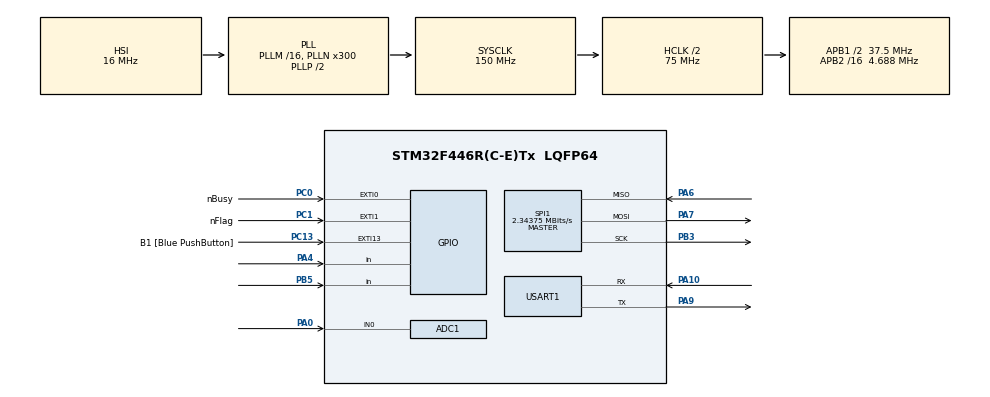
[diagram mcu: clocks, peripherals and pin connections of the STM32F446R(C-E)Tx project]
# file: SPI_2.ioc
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ADC1.Channel-1\#ChannelRegularConversion=ADC_CHANNEL_0
ADC1.NbrOfConversionFlag=1
ADC1.Rank-1\#ChannelRegularConversion=1
ADC1.SamplingTime-1\#ChannelRegularConversion=ADC_SAMPLETIME_3CYCLES
ADC1.master=1
FREERTOS.Tasks01=defaultTask,24,128,StartDefaultTask,Default,NULL,Dynamic,NULL,NULL
FREERTOS.configUSE_NEWLIB_REENTRANT=1
Mcu.Family=STM32F4
Mcu.Name=STM32F446R(C-E)Tx
Mcu.Package=LQFP64
NVIC.EXTI0_IRQn=true\:5\:0\:false\:false\:true\:true\:true\:true\:true
NVIC.EXTI15_10_IRQn=true\:5\:0\:false\:false\:true\:true\:true\:true\:true
NVIC.EXTI1_IRQn=true\:5\:0\:false\:false\:true\:true\:true\:true\:true
NVIC.PriorityGroup=NVIC_PRIORITYGROUP_4
NVIC.TIM1_UP_TIM10_IRQn=true\:15\:0\:false\:false\:true\:false\:false\:true\:true
NVIC.TimeBase=TIM1_UP_TIM10_IRQn
NVIC.TimeBaseIP=TIM1
PA0-WKUP.Signal=ADCx_IN0
PA10.Mode=Asynchronous
PA10.Signal=USART1_RX
PA13.GPIO_Label=TMS
PA13.Mode=Serial_Wire
PA13.Signal=SYS_JTMS-SWDIO
PA14.GPIO_Label=TCK
PA14.Mode=Serial_Wire
PA14.Signal=SYS_JTCK-SWCLK
PA2.GPIO_Label=USART_TX
PA2.Signal=USART2_TX
PA3.GPIO_Label=USART_RX
PA3.Signal=USART2_RX
PA4.Signal=GPIO_Input
PA6.Mode=Full_Duplex_Master
PA6.Signal=SPI1_MISO
PA7.Mode=Full_Duplex_Master
PA7.Signal=SPI1_MOSI
PA9.Mode=Asynchronous
PA9.Signal=USART1_TX
PB3.Mode=Full_Duplex_Master
PB3.Signal=SPI1_SCK
PB5.Signal=GPIO_Input
PC0.GPIO_Label=nBusy
PC0.Signal=GPXTI0
PC1.GPIO_Label=nFlag
PC1.Signal=GPXTI1
PC13.GPIO_Label=B1 [Blue PushButton]
PC13.GPIO_ModeDefaultEXTI=GPIO_MODE_IT_FALLING
PC13.Signal=GPXTI13
PC14-OSC32_IN.Mode=LSE-External-Oscillator
PC14-OSC32_IN.Signal=RCC_OSC32_IN
PC15-OSC32_OUT.Mode=LSE-External-Oscillator
PC15-OSC32_OUT.Signal=RCC_OSC32_OUT
PH0-OSC_IN.Mode=HSE-External-Oscillator
PH0-OSC_IN.Signal=RCC_OSC_IN
PH1-OSC_OUT.Mode=HSE-External-Oscillator
PH1-OSC_OUT.Signal=RCC_OSC_OUT
ProjectManager.HeapSize=0x200
ProjectManager.StackSize=0x400
ProjectManager.TargetToolchain=STM32CubeIDE
RCC.48MHZClocksFreq_Value=84000000
RCC.AHBCLKDivider=RCC_SYSCLK_DIV2
RCC.AHBFreq_Value=75000000
RCC.APB1CLKDivider=RCC_HCLK_DIV2
RCC.APB1Freq_Value=37500000
RCC.APB1TimFreq_Value=75000000
RCC.APB2CLKDivider=RCC_HCLK_DIV16
RCC.APB2Freq_Value=4687500
RCC.APB2TimFreq_Value=9375000
RCC.CortexFreq_Value=75000000
RCC.FLatency-AdvancedSettings=FLASH_LATENCY_2
RCC.HCLKFreq_Value=75000000
RCC.HSE_VALUE=8000000
RCC.HSI_VALUE=16000000
RCC.PLLN=300
RCC.SYSCLKFreq_VALUE=150000000
RCC.SYSCLKSource=RCC_SYSCLKSOURCE_PLLCLK
RCC.USBFreq_Value=150000000
RCC.VCOOutputFreq_Value=300000000
SH.ADCx_IN0.0=ADC1_IN0,IN0
SPI1.CalculateBaudRate=2.34375 MBits/s
SPI1.Direction=SPI_DIRECTION_2LINES
SPI1.Mode=SPI_MODE_MASTER
SPI1.VirtualType=VM_MASTER
USART1.VirtualMode=VM_ASYNC
VP_FREERTOS_VS_CMSIS_V2.Mode=CMSIS_V2
VP_SYS_VS_tim1.Mode=TIM1
board=NUCLEO-F446RE

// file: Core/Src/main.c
/* USER CODE BEGIN Header */
/**
 ******************************************************************************
 * @file           : main.c
 * @brief          : Main program body
 ******************************************************************************
 * @attention
 *
 * Copyright (c) 2024 STMicroelectronics.
 * All rights reserved.
 *
 * This software is licensed under terms that can be found in the LICENSE file
 * in the root directory of this software component.
 * If no LICENSE file comes with this software, it is provided AS-IS.
 *
 ******************************************************************************
 */
/* USER CODE END Header */
#include "main.h"
#include "cmsis_os.h"

/* USER CODE BEGIN Includes */

#include "xnucleoihm02a1.h"
#include "example.h"

/* USER CODE END Includes */

ADC_HandleTypeDef hadc1;

SPI_HandleTypeDef hspi1;

UART_HandleTypeDef huart1;

/* Definitions for defaultTask */
osThreadId_t defaultTaskHandle;
const osThreadAttr_t defaultTask_attributes = {
  .name = "defaultTask",
  .stack_size = 128 * 4,
  .priority = (osPriority_t) osPriorityNormal,
};

void SystemClock_Config(void);
static void MX_GPIO_Init(void);
static void MX_ADC1_Init(void);
static void MX_SPI1_Init(void);
static void MX_USART1_UART_Init(void);
void StartDefaultTask(void *argument);

int main(void)
{

  /* MCU Configuration--------------------------------------------------------*/

  /* Reset of all peripherals, Initializes the Flash interface and the Systick. */
  HAL_Init();

  /* Configure the system clock */
  SystemClock_Config();

  /* Initialize all configured peripherals */
  MX_GPIO_Init();
  MX_ADC1_Init();
  MX_SPI1_Init();
  MX_USART1_UART_Init();
  /* USER CODE BEGIN 2 */

	/* Init specifique du XNUCLEO02A01 */
	BSP_Init();

  /* USER CODE END 2 */

  /* Init scheduler */
  osKernelInitialize();

  /* Create the thread(s) */
  /* creation of defaultTask */
  defaultTaskHandle = osThreadNew(StartDefaultTask, NULL, &defaultTask_attributes);

  /* Start scheduler */
  osKernelStart();

  /* We should never get here as control is now taken by the scheduler */

  /* Infinite loop */
	while (1)
	{

	}
}

void SystemClock_Config(void)
{
  RCC_OscInitTypeDef RCC_OscInitStruct = {0};
  RCC_ClkInitTypeDef RCC_ClkInitStruct = {0};

  /** Configure the main internal regulator output voltage
  */
  __HAL_RCC_PWR_CLK_ENABLE();
  __HAL_PWR_VOLTAGESCALING_CONFIG(PWR_REGULATOR_VOLTAGE_SCALE3);

  /** Initializes the RCC Oscillators according to the specified parameters
  * in the RCC_OscInitTypeDef structure.
  */
  RCC_OscInitStruct.OscillatorType = RCC_OSCILLATORTYPE_HSI;
  RCC_OscInitStruct.HSIState = RCC_HSI_ON;
  RCC_OscInitStruct.HSICalibrationValue = RCC_HSICALIBRATION_DEFAULT;
  RCC_OscInitStruct.PLL.PLLState = RCC_PLL_ON;
  RCC_OscInitStruct.PLL.PLLSource = RCC_PLLSOURCE_HSI;
  RCC_OscInitStruct.PLL.PLLM = 16;
  RCC_OscInitStruct.PLL.PLLN = 300;
  RCC_OscInitStruct.PLL.PLLP = RCC_PLLP_DIV2;
  RCC_OscInitStruct.PLL.PLLQ = 2;
  RCC_OscInitStruct.PLL.PLLR = 2;
  if (HAL_RCC_OscConfig(&RCC_OscInitStruct) != HAL_OK)
  {
    Error_Handler();
  }

  /** Initializes the CPU, AHB and APB buses clocks
  */
  RCC_ClkInitStruct.ClockType = RCC_CLOCKTYPE_HCLK|RCC_CLOCKTYPE_SYSCLK
                              |RCC_CLOCKTYPE_PCLK1|RCC_CLOCKTYPE_PCLK2;
  RCC_ClkInitStruct.SYSCLKSource = RCC_SYSCLKSOURCE_PLLCLK;
  RCC_ClkInitStruct.AHBCLKDivider = RCC_SYSCLK_DIV2;
  RCC_ClkInitStruct.APB1CLKDivider = RCC_HCLK_DIV2;
  RCC_ClkInitStruct.APB2CLKDivider = RCC_HCLK_DIV16;

  if (HAL_RCC_ClockConfig(&RCC_ClkInitStruct, FLASH_LATENCY_2) != HAL_OK)
  {
    Error_Handler();
  }
}

static void MX_ADC1_Init(void)
{

  ADC_ChannelConfTypeDef sConfig = {0};

  /** Configure the global features of the ADC (Clock, Resolution, Data Alignment and number of conversion)
  */
  hadc1.Instance = ADC1;
  hadc1.Init.ClockPrescaler = ADC_CLOCK_SYNC_PCLK_DIV2;
  hadc1.Init.Resolution = ADC_RESOLUTION_12B;
  hadc1.Init.ScanConvMode = DISABLE;
  hadc1.Init.ContinuousConvMode = DISABLE;
  hadc1.Init.DiscontinuousConvMode = DISABLE;
  hadc1.Init.ExternalTrigConvEdge = ADC_EXTERNALTRIGCONVEDGE_NONE;
  hadc1.Init.ExternalTrigConv = ADC_SOFTWARE_START;
  hadc1.Init.DataAlign = ADC_DATAALIGN_RIGHT;
  hadc1.Init.NbrOfConversion = 1;
  hadc1.Init.DMAContinuousRequests = DISABLE;
  hadc1.Init.EOCSelection = ADC_EOC_SINGLE_CONV;
  if (HAL_ADC_Init(&hadc1) != HAL_OK)
  {
    Error_Handler();
  }

  /** Configure for the selected ADC regular channel its corresponding rank in the sequencer and its sample time.
  */
  sConfig.Channel = ADC_CHANNEL_0;
  sConfig.Rank = 1;
  sConfig.SamplingTime = ADC_SAMPLETIME_3CYCLES;
  if (HAL_ADC_ConfigChannel(&hadc1, &sConfig) != HAL_OK)
  {
    Error_Handler();
  }

}

static void MX_SPI1_Init(void)
{

  /* SPI1 parameter configuration*/
  hspi1.Instance = SPI1;
  hspi1.Init.Mode = SPI_MODE_MASTER;
  hspi1.Init.Direction = SPI_DIRECTION_2LINES;
  hspi1.Init.DataSize = SPI_DATASIZE_8BIT;
  hspi1.Init.CLKPolarity = SPI_POLARITY_LOW;
  hspi1.Init.CLKPhase = SPI_PHASE_1EDGE;
  hspi1.Init.NSS = SPI_NSS_SOFT;
  hspi1.Init.BaudRatePrescaler = SPI_BAUDRATEPRESCALER_2;
  hspi1.Init.FirstBit = SPI_FIRSTBIT_MSB;
  hspi1.Init.TIMode = SPI_TIMODE_DISABLE;
  hspi1.Init.CRCCalculation = SPI_CRCCALCULATION_DISABLE;
  hspi1.Init.CRCPolynomial = 10;
  if (HAL_SPI_Init(&hspi1) != HAL_OK)
  {
    Error_Handler();
  }
  /* USER CODE BEGIN SPI1_Init 2 */
  hspi1.Init.CRCPolynomial = 7;
  /* USER CODE END SPI1_Init 2 */

}

static void MX_USART1_UART_Init(void)
{

  huart1.Instance = USART1;
  huart1.Init.BaudRate = 115200;
  huart1.Init.WordLength = UART_WORDLENGTH_8B;
  huart1.Init.StopBits = UART_STOPBITS_1;
  huart1.Init.Parity = UART_PARITY_NONE;
  huart1.Init.Mode = UART_MODE_TX_RX;
  huart1.Init.HwFlowCtl = UART_HWCONTROL_NONE;
  huart1.Init.OverSampling = UART_OVERSAMPLING_16;
  if (HAL_UART_Init(&huart1) != HAL_OK)
  {
    Error_Handler();
  }

}

static void MX_GPIO_Init(void)
{
  GPIO_InitTypeDef GPIO_InitStruct = {0};

  /* GPIO Ports Clock Enable */
  __HAL_RCC_GPIOC_CLK_ENABLE();
  __HAL_RCC_GPIOH_CLK_ENABLE();
  __HAL_RCC_GPIOA_CLK_ENABLE();
  __HAL_RCC_GPIOB_CLK_ENABLE();

  /*Configure GPIO pin : B1_Pin */
  GPIO_InitStruct.Pin = B1_Pin;
  GPIO_InitStruct.Mode = GPIO_MODE_IT_FALLING;
  GPIO_InitStruct.Pull = GPIO_NOPULL;
  HAL_GPIO_Init(B1_GPIO_Port, &GPIO_InitStruct);

  /*Configure GPIO pins : nBusy_Pin nFlag_Pin */
  GPIO_InitStruct.Pin = nBusy_Pin|nFlag_Pin;
  GPIO_InitStruct.Mode = GPIO_MODE_IT_RISING;
  GPIO_InitStruct.Pull = GPIO_NOPULL;
  HAL_GPIO_Init(GPIOC, &GPIO_InitStruct);

  /*Configure GPIO pins : USART_TX_Pin USART_RX_Pin */
  GPIO_InitStruct.Pin = USART_TX_Pin|USART_RX_Pin;
  GPIO_InitStruct.Mode = GPIO_MODE_AF_PP;
  GPIO_InitStruct.Pull = GPIO_NOPULL;
  GPIO_InitStruct.Speed = GPIO_SPEED_FREQ_VERY_HIGH;
  GPIO_InitStruct.Alternate = GPIO_AF7_USART2;
  HAL_GPIO_Init(GPIOA, &GPIO_InitStruct);

  /*Configure GPIO pin : PA4 */
  GPIO_InitStruct.Pin = GPIO_PIN_4;
  GPIO_InitStruct.Mode = GPIO_MODE_INPUT;
  GPIO_InitStruct.Pull = GPIO_NOPULL;
  HAL_GPIO_Init(GPIOA, &GPIO_InitStruct);

  /*Configure GPIO pin : PB5 */
  GPIO_InitStruct.Pin = GPIO_PIN_5;
  GPIO_InitStruct.Mode = GPIO_MODE_INPUT;
  GPIO_InitStruct.Pull = GPIO_NOPULL;
  HAL_GPIO_Init(GPIOB, &GPIO_InitStruct);

  /* EXTI interrupt init*/
  HAL_NVIC_SetPriority(EXTI0_IRQn, 5, 0);
  HAL_NVIC_EnableIRQ(EXTI0_IRQn);

  HAL_NVIC_SetPriority(EXTI1_IRQn, 5, 0);
  HAL_NVIC_EnableIRQ(EXTI1_IRQn);

  HAL_NVIC_SetPriority(EXTI15_10_IRQn, 5, 0);
  HAL_NVIC_EnableIRQ(EXTI15_10_IRQn);

}

void StartDefaultTask(void *argument)
{
  /* USER CODE BEGIN 5 */
	/* Infinite loop */

	while(1)
	{
		MicrosteppingMotor_Example_03();
	}

	for(;;)
	{
		osDelay(1);
	}
  /* USER CODE END 5 */
}

void HAL_TIM_PeriodElapsedCallback(TIM_HandleTypeDef *htim)
{
  if (htim->Instance == TIM1) {
    HAL_IncTick();
  }
}

void Error_Handler(void)
{
	__disable_irq();
	while (1)
	{
	}
}
